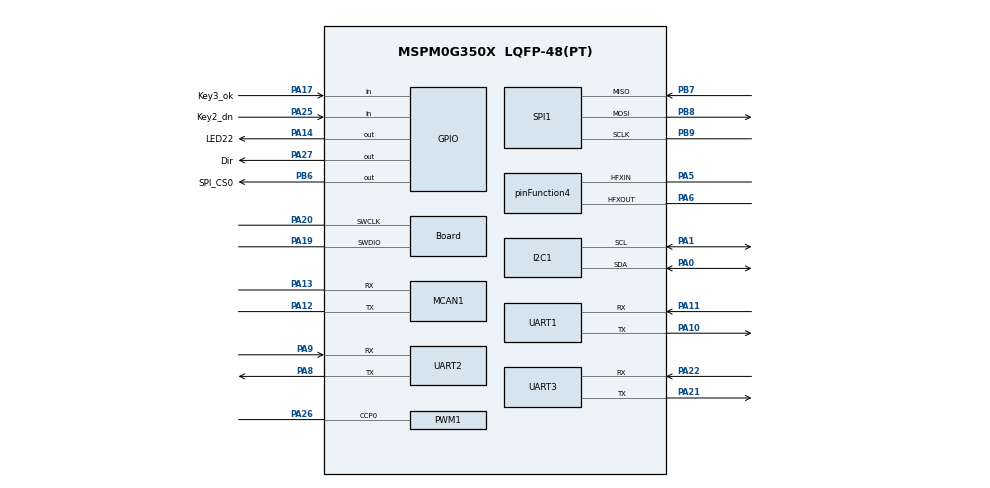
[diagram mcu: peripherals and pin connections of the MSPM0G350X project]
/**
 *
 * @cliArgs --device "MSPM0G350X" --part "Default" --package "LQFP-48(PT)" --product "mspm0_sdk@2.10.00.04"
 * @versions {"tool":"1.28.0+4712"}
 */

/**
 * Import the modules used in this configuration.
 */
const GPIO   = scripting.addModule("/ti/driverlib/GPIO", {}, false);
const GPIO1  = GPIO.addInstance();
const GPIO2  = GPIO.addInstance();
const GPIO3  = GPIO.addInstance();
const GPIO4  = GPIO.addInstance();
const I2C    = scripting.addModule("/ti/driverlib/I2C", {}, false);
const I2C1   = I2C.addInstance();
const MCAN   = scripting.addModule("/ti/driverlib/MCAN", {}, false);
const MCAN1  = MCAN.addInstance();
const PWM    = scripting.addModule("/ti/driverlib/PWM", {}, false);
const PWM1   = PWM.addInstance();
const SPI    = scripting.addModule("/ti/driverlib/SPI", {}, false);
const SPI1   = SPI.addInstance();
const SYSCTL = scripting.addModule("/ti/driverlib/SYSCTL");
const TIMER  = scripting.addModule("/ti/driverlib/TIMER", {}, false);
const TIMER1 = TIMER.addInstance();
const UART   = scripting.addModule("/ti/driverlib/UART", {}, false);
const UART1  = UART.addInstance();
const UART2  = UART.addInstance();
const UART3  = UART.addInstance();

/**
 * Write custom configuration values to the imported modules.
 */
const divider5       = system.clockTree["PLL_CLK1_DIV"];
divider5.divideValue = 4;

const divider6       = system.clockTree["PLL_CLK2X_DIV"];
divider6.divideValue = 4;

const divider9       = system.clockTree["UDIV"];
divider9.divideValue = 2;

const multiplier2         = system.clockTree["PLL_QDIV"];
multiplier2.multiplyValue = 4;

const mux4       = system.clockTree["EXHFMUX"];
mux4.inputSelect = "EXHFMUX_XTAL";

const mux8       = system.clockTree["HSCLKMUX"];
mux8.inputSelect = "HSCLKMUX_SYSPLL0";

const mux12       = system.clockTree["SYSPLLMUX"];
mux12.inputSelect = "zSYSPLLMUX_HFCLK";

const pinFunction4                        = system.clockTree["HFXT"];
pinFunction4.enable                       = true;
pinFunction4.inputFreq                    = 40;
pinFunction4.HFCLKMonitor                 = true;
pinFunction4.HFXTStartup                  = 10;
pinFunction4.peripheral.$assign           = "SYSCTL";
pinFunction4.peripheral.hfxInPin.$assign  = "PA5";
pinFunction4.peripheral.hfxOutPin.$assign = "PA6";

GPIO1.$name                         = "LED";
GPIO1.associatedPins[0].$name       = "LED22";
GPIO1.associatedPins[0].pin.$assign = "PA14";

const Board                       = scripting.addModule("/ti/driverlib/Board", {}, false);
Board.peripheral.$assign          = "DEBUGSS";
Board.peripheral.swclkPin.$assign = "PA20";
Board.peripheral.swdioPin.$assign = "PA19";

GPIO2.$name                          = "SPI_CS";
GPIO2.associatedPins[0].$name        = "SPI_CS0";
GPIO2.associatedPins[0].assignedPort = "PORTB";
GPIO2.associatedPins[0].initialValue = "SET";
GPIO2.associatedPins[0].pin.$assign  = "PB6";

GPIO3.$name                         = "STP_pins";
GPIO3.associatedPins[0].$name       = "Dir";
GPIO3.associatedPins[0].pin.$assign = "PA27";

GPIO4.$name                              = "Keys";
GPIO4.associatedPins.create(3);
GPIO4.associatedPins[0].direction        = "INPUT";
GPIO4.associatedPins[0].assignedPort     = "PORTA";
GPIO4.associatedPins[0].$name            = "Key1_up";
GPIO4.associatedPins[0].internalResistor = "PULL_UP";
GPIO4.associatedPins[1].$name            = "Key2_dn";
GPIO4.associatedPins[1].direction        = "INPUT";
GPIO4.associatedPins[1].internalResistor = "PULL_UP";
GPIO4.associatedPins[1].pin.$assign      = "PA25";
GPIO4.associatedPins[2].$name            = "Key3_ok";
GPIO4.associatedPins[2].direction        = "INPUT";
GPIO4.associatedPins[2].internalResistor = "PULL_UP";
GPIO4.associatedPins[2].pin.$assign      = "PA17";

I2C1.$name                     = "I2C_0";
I2C1.basicEnableController     = true;
I2C1.basicClockSourceDivider   = 4;
I2C1.basicControllerBusSpeed   = 500000;
I2C1.peripheral.$assign        = "I2C0";
I2C1.peripheral.sdaPin.$assign = "PA0";
I2C1.peripheral.sclPin.$assign = "PA1";
I2C1.sdaPinConfig.$name        = "ti_driverlib_gpio_GPIOPinGeneric8";
I2C1.sclPinConfig.$name        = "ti_driverlib_gpio_GPIOPinGeneric9";

MCAN1.$name                    = "MCAN0";
MCAN1.desiredNomRate           = 250;
MCAN1.enableInterrupt          = true;
MCAN1.m0interrupts             = ["DL_MCAN_MSP_INTERRUPT_LINE1"];
MCAN1.interruptLine            = ["DL_MCAN_INTR_LINE_NUM_1"];
MCAN1.interruptFlags           = ["DL_MCAN_INTR_MASK_ALL"];
MCAN1.interruptLine1Flag       = ["DL_MCAN_INTR_MASK_ALL"];
MCAN1.peripheral.$assign       = "CANFD0";
MCAN1.peripheral.rxPin.$assign = "PA13";
MCAN1.peripheral.txPin.$assign = "PA12";
MCAN1.txPinConfig.$name        = "ti_driverlib_gpio_GPIOPinGeneric5";
MCAN1.rxPinConfig.$name        = "ti_driverlib_gpio_GPIOPinGeneric10";

PWM1.$name                              = "PWM_Step";
PWM1.ccIndex                            = [0];
PWM1.clockPrescale                      = 79;
PWM1.PWM_CHANNEL_0.$name                = "ti_driverlib_pwm_PWMTimerCC0";
PWM1.ccp0PinConfig.$name                = "ti_driverlib_gpio_GPIOPinGeneric4";
PWM1.ccp0PinConfig.direction            = scripting.forceWrite("OUTPUT");
PWM1.ccp0PinConfig.hideOutputInversion  = scripting.forceWrite(false);
PWM1.ccp0PinConfig.onlyInternalResistor = scripting.forceWrite(false);
PWM1.ccp0PinConfig.passedPeripheralType = scripting.forceWrite("Digital");
PWM1.peripheral.$assign                 = "TIMG7";
PWM1.peripheral.ccp0Pin.$assign         = "PA26";

SPI1.$name                              = "SPI_1";
SPI1.polarity                           = "1";
SPI1.phase                              = "1";
SPI1.peripheral.$assign                 = "SPI1";
SPI1.peripheral.sclkPin.$assign         = "PB9";
SPI1.peripheral.mosiPin.$assign         = "PB8";
SPI1.peripheral.misoPin.$assign         = "PB7";
SPI1.sclkPinConfig.direction            = scripting.forceWrite("OUTPUT");
SPI1.sclkPinConfig.onlyInternalResistor = scripting.forceWrite(false);
SPI1.sclkPinConfig.passedPeripheralType = scripting.forceWrite("Digital");
SPI1.sclkPinConfig.$name                = "ti_driverlib_gpio_GPIOPinGeneric2";
SPI1.sclkPinConfig.enableConfig         = true;
SPI1.mosiPinConfig.direction            = scripting.forceWrite("OUTPUT");
SPI1.mosiPinConfig.hideOutputInversion  = scripting.forceWrite(false);
SPI1.mosiPinConfig.onlyInternalResistor = scripting.forceWrite(false);
SPI1.mosiPinConfig.passedPeripheralType = scripting.forceWrite("Digital");
SPI1.mosiPinConfig.$name                = "ti_driverlib_gpio_GPIOPinGeneric3";
SPI1.mosiPinConfig.enableConfig         = true;
SPI1.misoPinConfig.onlyInternalResistor = scripting.forceWrite(false);
SPI1.misoPinConfig.passedPeripheralType = scripting.forceWrite("Digital");
SPI1.misoPinConfig.$name                = "ti_driverlib_gpio_GPIOPinGeneric6";
SPI1.misoPinConfig.enableConfig         = true;
SPI1.cs0PinConfig.direction             = scripting.forceWrite("OUTPUT");
SPI1.cs0PinConfig.hideOutputInversion   = scripting.forceWrite(false);
SPI1.cs0PinConfig.onlyInternalResistor  = scripting.forceWrite(false);
SPI1.cs0PinConfig.passedPeripheralType  = scripting.forceWrite("Digital");
SPI1.cs0PinConfig.$name                 = "ti_driverlib_gpio_GPIOPinGeneric7";

SYSCTL.forceDefaultClkConfig = true;
SYSCTL.clockTreeEn           = true;

TIMER1.$name              = "TIMER_TICK";
TIMER1.timerClkDiv        = 8;
TIMER1.timerClkPrescale   = 10;
TIMER1.timerMode          = "PERIODIC";
TIMER1.timerStartTimer    = true;
TIMER1.interrupts         = ["ZERO"];
TIMER1.interruptPriority  = "3";
TIMER1.timerPeriod        = "1 ms";
TIMER1.peripheral.$assign = "TIMA0";

UART1.$name                            = "UART_DEBUG";
UART1.enabledInterrupts                = ["RX"];
UART1.interruptPriority                = "3";
UART1.targetBaudRate                   = 115200;
UART1.peripheral.$assign               = "UART0";
UART1.peripheral.rxPin.$assign         = "PA11";
UART1.peripheral.txPin.$assign         = "PA10";
UART1.txPinConfig.direction            = scripting.forceWrite("OUTPUT");
UART1.txPinConfig.hideOutputInversion  = scripting.forceWrite(false);
UART1.txPinConfig.onlyInternalResistor = scripting.forceWrite(false);
UART1.txPinConfig.passedPeripheralType = scripting.forceWrite("Digital");
UART1.txPinConfig.$name                = "ti_driverlib_gpio_GPIOPinGeneric0";
UART1.rxPinConfig.hideOutputInversion  = scripting.forceWrite(false);
UART1.rxPinConfig.onlyInternalResistor = scripting.forceWrite(false);
UART1.rxPinConfig.passedPeripheralType = scripting.forceWrite("Digital");
UART1.rxPinConfig.$name                = "ti_driverlib_gpio_GPIOPinGeneric1";

UART2.$name                            = "UART_Tly";
UART2.targetBaudRate                   = 115200;
UART2.interruptPriority                = "3";
UART2.enabledInterrupts                = ["RX"];
UART2.peripheral.$assign               = "UART1";
UART2.peripheral.rxPin.$assign         = "PA9";
UART2.peripheral.txPin.$assign         = "PA8";
UART2.txPinConfig.$name                = "ti_driverlib_gpio_GPIOPinGeneric12";
UART2.txPinConfig.direction            = scripting.forceWrite("OUTPUT");
UART2.txPinConfig.hideOutputInversion  = scripting.forceWrite(false);
UART2.txPinConfig.onlyInternalResistor = scripting.forceWrite(false);
UART2.txPinConfig.passedPeripheralType = scripting.forceWrite("Digital");
UART2.rxPinConfig.$name                = "ti_driverlib_gpio_GPIOPinGeneric13";
UART2.rxPinConfig.hideOutputInversion  = scripting.forceWrite(false);
UART2.rxPinConfig.onlyInternalResistor = scripting.forceWrite(false);
UART2.rxPinConfig.passedPeripheralType = scripting.forceWrite("Digital");

UART3.$name                            = "UART_IMU601";
UART3.targetBaudRate                   = 115200;
UART3.enabledInterrupts                = ["RX"];
UART3.interruptPriority                = "3";
UART3.peripheral.$assign               = "UART2";
UART3.peripheral.rxPin.$assign         = "PA22";
UART3.peripheral.txPin.$assign         = "PA21";
UART3.txPinConfig.direction            = scripting.forceWrite("OUTPUT");
UART3.txPinConfig.hideOutputInversion  = scripting.forceWrite(false);
UART3.txPinConfig.onlyInternalResistor = scripting.forceWrite(false);
UART3.txPinConfig.passedPeripheralType = scripting.forceWrite("Digital");
UART3.txPinConfig.$name                = "ti_driverlib_gpio_GPIOPinGeneric11";
UART3.rxPinConfig.hideOutputInversion  = scripting.forceWrite(false);
UART3.rxPinConfig.onlyInternalResistor = scripting.forceWrite(false);
UART3.rxPinConfig.passedPeripheralType = scripting.forceWrite("Digital");
UART3.rxPinConfig.$name                = "ti_driverlib_gpio_GPIOPinGeneric14";

const ProjectConfig              = scripting.addModule("/ti/project_config/ProjectConfig", {}, false);
ProjectConfig.migrationCondition = true;

/**
 * Pinmux solution for unlocked pins/peripherals. This ensures that minor changes to the automatic solver in a future
 * version of the tool will not impact the pinmux you originally saw.  These lines can be completely deleted in order to
 * re-solve from scratch.
 */
GPIO4.associatedPins[0].pin.$suggestSolution = "PA28";
SPI1.peripheral.cs0Pin.$suggestSolution      = "PA2";
